VERSION ""

NS_ :

BS_:

BU_:

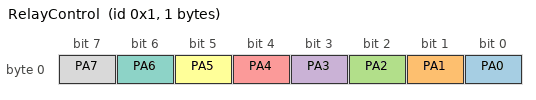
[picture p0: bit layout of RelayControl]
BO_ 1 RelayControl: 1 Vector__XXX
	SG_ PA0 : 0|1@1+ (1,0) [0|1] "" Vector__XXX
	SG_ PA1 : 1|1@1+ (1,0) [0|1] "" Vector__XXX
	SG_ PA2 : 2|1@1+ (1,0) [0|1] "" Vector__XXX
	SG_ PA3 : 3|1@1+ (1,0) [0|1] "" Vector__XXX
	SG_ PA4 : 4|1@1+ (1,0) [0|1] "" Vector__XXX
	SG_ PA5 : 5|1@1+ (1,0) [0|1] "" Vector__XXX
	SG_ PA6 : 6|1@1+ (1,0) [0|1] "" Vector__XXX
	SG_ PA7 : 7|1@1+ (1,0) [0|1] "" Vector__XXX

CM_ BO_ 1 "Control state of relays";
CM_ SG_ 1 PA0_Control "PIN A0 control";
CM_ SG_ 1 PA1_Control "PIN A1 control";
CM_ SG_ 1 PA2_Control "PIN A2 control";
CM_ SG_ 1 PA3_Control "PIN A3 control";
CM_ SG_ 1 PA4_Control "PIN A4 control";
CM_ SG_ 1 PA5_Control "PIN A5 control";
CM_ SG_ 1 PA6_Control "PIN A6 control";
CM_ SG_ 1 PA7_Control "PIN A7 control";

BA_DEF_ BO_  "VFrameFormat" ENUM  "StandardCAN","ExtendedCAN","reserved","J1939PG";
BA_DEF_DEF_  "VFrameFormat" "StandardCAN";
